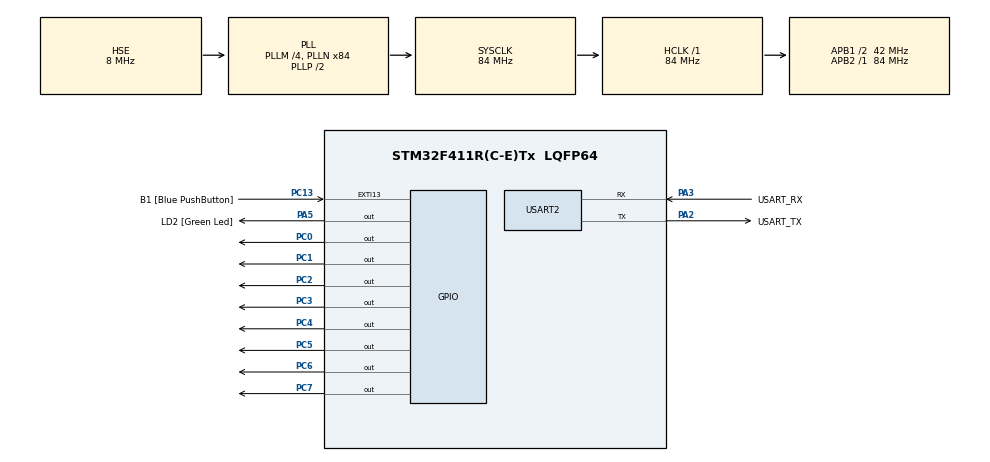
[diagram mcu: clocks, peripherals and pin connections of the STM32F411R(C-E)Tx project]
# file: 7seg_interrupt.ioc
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Mcu.Family=STM32F4
Mcu.Name=STM32F411R(C-E)Tx
Mcu.Package=LQFP64
NVIC.PVD_IRQn=true\:0\:0\:false\:false\:true\:true\:true\:true
NVIC.PriorityGroup=NVIC_PRIORITYGROUP_0
NVIC.TIM2_IRQn=true\:0\:0\:false\:false\:true\:true\:true\:true
PA13.GPIO_Label=TMS
PA13.Mode=Serial_Wire
PA13.Signal=SYS_JTMS-SWDIO
PA14.GPIO_Label=TCK
PA14.Mode=Serial_Wire
PA14.Signal=SYS_JTCK-SWCLK
PA2.GPIO_Label=USART_TX
PA2.Mode=Asynchronous
PA2.Signal=USART2_TX
PA3.GPIO_Label=USART_RX
PA3.Mode=Asynchronous
PA3.Signal=USART2_RX
PA5.GPIO_Label=LD2 [Green Led]
PA5.Signal=GPIO_Output
PB3.GPIO_Label=SWO
PB3.Signal=SYS_JTDO-SWO
PC0.Signal=GPIO_Output
PC1.Signal=GPIO_Output
PC13-ANTI_TAMP.GPIO_Label=B1 [Blue PushButton]
PC13-ANTI_TAMP.GPIO_ModeDefaultEXTI=GPIO_MODE_IT_RISING_FALLING
PC13-ANTI_TAMP.Signal=GPXTI13
PC14-OSC32_IN.Mode=LSE-External-Oscillator
PC14-OSC32_IN.Signal=RCC_OSC32_IN
PC15-OSC32_OUT.Mode=LSE-External-Oscillator
PC15-OSC32_OUT.Signal=RCC_OSC32_OUT
PC2.Signal=GPIO_Output
PC3.Signal=GPIO_Output
PC4.Signal=GPIO_Output
PC5.Signal=GPIO_Output
PC6.Signal=GPIO_Output
PC7.Signal=GPIO_Output
PH0\ -\ OSC_IN.Mode=HSE-External-Clock-Source
PH0\ -\ OSC_IN.Signal=RCC_OSC_IN
PH1\ -\ OSC_OUT.Mode=HSE-External-Clock-Source
PH1\ -\ OSC_OUT.Signal=RCC_OSC_OUT
ProjectManager.HeapSize=0x200
ProjectManager.StackSize=0x400
ProjectManager.TargetToolchain=STM32CubeIDE
RCC.48MHZClocksFreq_Value=42000000
RCC.AHBFreq_Value=84000000
RCC.APB1CLKDivider=RCC_HCLK_DIV2
RCC.APB1Freq_Value=42000000
RCC.APB1TimFreq_Value=84000000
RCC.APB2Freq_Value=84000000
RCC.APB2TimFreq_Value=84000000
RCC.CortexFreq_Value=84000000
RCC.FLatency-AdvancedSettings=FLASH_LATENCY_2
RCC.HCLKFreq_Value=84000000
RCC.HSE_VALUE=8000000
RCC.HSI_VALUE=16000000
RCC.PLLM=4
RCC.PLLN=84
RCC.PLLSourceVirtual=RCC_PLLSOURCE_HSE
RCC.SYSCLKFreq_VALUE=84000000
RCC.SYSCLKSource=RCC_SYSCLKSOURCE_PLLCLK
RCC.VCOOutputFreq_Value=168000000
TIM2.Period=9999
TIM2.Prescaler=8399
USART2.VirtualMode=VM_ASYNC
VP_TIM2_VS_ClockSourceINT.Mode=Internal
board=NUCLEO-F411RE

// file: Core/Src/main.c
/* USER CODE BEGIN Header */
/**
  ******************************************************************************
  * @file           : main.c
  * @brief          : Main program body
  ******************************************************************************
  * @attention
  *
  * Copyright (c) 2024 STMicroelectronics.
  * All rights reserved.
  *
  * This software is licensed under terms that can be found in the LICENSE file
  * in the root directory of this software component.
  * If no LICENSE file comes with this software, it is provided AS-IS.
  *
  ******************************************************************************
  */
/* USER CODE END Header */
#include "main.h"

TIM_HandleTypeDef htim2;
UART_HandleTypeDef huart2;

/* USER CODE BEGIN PV */
static uint8_t currentNumber = 0;
static uint8_t displayEnabled = 1; // Flag to enable or disable the display
/* USER CODE END PV */

void SystemClock_Config(void);
static void MX_GPIO_Init(void);
static void MX_USART2_UART_Init(void);
static void MX_TIM2_Init(void);
/* USER CODE BEGIN PFP */
void EXTI0_IRQHandler(void);
void DisplayNumber(uint8_t number);
void TurnOffDisplay(void);
/* USER CODE END PFP */

int main(void)
{

  /* MCU Configuration--------------------------------------------------------*/

  /* Reset of all peripherals, Initializes the Flash interface and the Systick. */
  HAL_Init();

  /* Configure the system clock */
  SystemClock_Config();

  /* Initialize all configured peripherals */
  MX_GPIO_Init();
  MX_USART2_UART_Init();
  MX_TIM2_Init();

  /* USER CODE BEGIN 2 */
  HAL_TIM_Base_Start_IT(&htim2);  // Start TIM2 with interrupt
  HAL_NVIC_SetPriority(EXTI0_IRQn, 0, 0);  // Set priority for EXTI0 interrupt
  HAL_NVIC_EnableIRQ(EXTI0_IRQn);  // Enable EXTI0 interrupt
  /* USER CODE END 2 */

  /* Infinite loop */
  /* USER CODE BEGIN WHILE */
  while (1)
  {
    if (displayEnabled) {
        // Display is enabled, so TIM2 callback will handle the display update
    } else {
        TurnOffDisplay();
    }
    /* USER CODE END WHILE */
  }
}

void HAL_TIM_PeriodElapsedCallback(TIM_HandleTypeDef *htim)
{
    if (htim->Instance == TIM2) {
        if (displayEnabled) { // Check if display is enabled
            /* Update current number and display */
            currentNumber = (currentNumber + 1) % 10;
            DisplayNumber(currentNumber);
        }
    }
}

void DisplayNumber(uint8_t number)
{
    uint8_t segments[10] = {
        0x3F, // 0
        0x06, // 1
        0x5B, // 2
        0x4F, // 3
        0x66, // 4
        0x6D, // 5
        0x7D, // 6
        0x07, // 7
        0x7F, // 8
        0x6F  // 9
    };
    uint8_t segmentPattern = segments[number];

    HAL_GPIO_WritePin(GPIOC, GPIO_PIN_0, (segmentPattern & 0x01) ? GPIO_PIN_RESET : GPIO_PIN_SET); // Segment A
    HAL_GPIO_WritePin(GPIOC, GPIO_PIN_1, (segmentPattern & 0x02) ? GPIO_PIN_RESET : GPIO_PIN_SET); // Segment B
    HAL_GPIO_WritePin(GPIOC, GPIO_PIN_2, (segmentPattern & 0x04) ? GPIO_PIN_RESET : GPIO_PIN_SET); // Segment C
    HAL_GPIO_WritePin(GPIOC, GPIO_PIN_3, (segmentPattern & 0x08) ? GPIO_PIN_RESET : GPIO_PIN_SET); // Segment D
    HAL_GPIO_WritePin(GPIOC, GPIO_PIN_4, (segmentPattern & 0x10) ? GPIO_PIN_RESET : GPIO_PIN_SET); // Segment E
    HAL_GPIO_WritePin(GPIOC, GPIO_PIN_5, (segmentPattern & 0x20) ? GPIO_PIN_RESET : GPIO_PIN_SET); // Segment F
    HAL_GPIO_WritePin(GPIOC, GPIO_PIN_6, (segmentPattern & 0x40) ? GPIO_PIN_RESET : GPIO_PIN_SET); // Segment G
}

void TurnOffDisplay(void)
{
    // Turn off all segments of the 7-segment display
    HAL_GPIO_WritePin(GPIOC, GPIO_PIN_0|GPIO_PIN_1|GPIO_PIN_2|GPIO_PIN_3|GPIO_PIN_4|GPIO_PIN_5|GPIO_PIN_6, GPIO_PIN_SET);
}

void EXTI0_IRQHandler(void)
{
    HAL_GPIO_EXTI_IRQHandler(B1_Pin); // Handle the interrupt
}

void HAL_GPIO_EXTI_Callback(uint16_t GPIO_Pin)
{
    static uint32_t lastInterruptTime = 0;
    uint32_t currentTime = HAL_GetTick();  // Get current time in milliseconds

    if (GPIO_Pin == B1_Pin)
    {
        if (currentTime - lastInterruptTime > 200)  // 200 ms debounce time
        {
            displayEnabled = !displayEnabled; // Toggle the display enable flag
            HAL_GPIO_TogglePin(LD2_GPIO_Port, LD2_Pin); // Optional: Toggle LED to indicate state
        }
        lastInterruptTime = currentTime;
    }
}

void SystemClock_Config(void)
{
  RCC_OscInitTypeDef RCC_OscInitStruct = {0};
  RCC_ClkInitTypeDef RCC_ClkInitStruct = {0};

  /** Configure the main internal regulator output voltage
  */
  __HAL_RCC_PWR_CLK_ENABLE();
  __HAL_PWR_VOLTAGESCALING_CONFIG(PWR_REGULATOR_VOLTAGE_SCALE1);

  /** Initializes the RCC Oscillators according to the specified parameters
  * in the RCC_OscInitTypeDef structure.
  */
  RCC_OscInitStruct.OscillatorType = RCC_OSCILLATORTYPE_HSE;
  RCC_OscInitStruct.HSEState = RCC_HSE_BYPASS;
  RCC_OscInitStruct.PLL.PLLState = RCC_PLL_ON;
  RCC_OscInitStruct.PLL.PLLSource = RCC_PLLSOURCE_HSE;
  RCC_OscInitStruct.PLL.PLLM = 4;
  RCC_OscInitStruct.PLL.PLLN = 84;
  RCC_OscInitStruct.PLL.PLLP = RCC_PLLP_DIV2;
  RCC_OscInitStruct.PLL.PLLQ = 4;
  if (HAL_RCC_OscConfig(&RCC_OscInitStruct) != HAL_OK)
  {
    Error_Handler();
  }

  /** Initializes the CPU, AHB and APB buses clocks
  */
  RCC_ClkInitStruct.ClockType = RCC_CLOCKTYPE_HCLK|RCC_CLOCKTYPE_SYSCLK
                              |RCC_CLOCKTYPE_PCLK1|RCC_CLOCKTYPE_PCLK2;
  RCC_ClkInitStruct.SYSCLKSource = RCC_SYSCLKSOURCE_PLLCLK;
  RCC_ClkInitStruct.AHBCLKDivider = RCC_SYSCLK_DIV1;
  RCC_ClkInitStruct.APB1CLKDivider = RCC_HCLK_DIV2;
  RCC_ClkInitStruct.APB2CLKDivider = RCC_HCLK_DIV1;

  if (HAL_RCC_ClockConfig(&RCC_ClkInitStruct, FLASH_LATENCY_2) != HAL_OK)
  {
    Error_Handler();
  }
}

static void MX_TIM2_Init(void)
{
  TIM_ClockConfigTypeDef sClockSourceConfig = {0};
  TIM_MasterConfigTypeDef sMasterConfig = {0};

  htim2.Instance = TIM2;
  htim2.Init.Prescaler = 8399;
  htim2.Init.CounterMode = TIM_COUNTERMODE_UP;
  htim2.Init.Period = 9999;
  htim2.Init.ClockDivision = TIM_CLOCKDIVISION_DIV1;
  htim2.Init.AutoReloadPreload = TIM_AUTORELOAD_PRELOAD_DISABLE;
  if (HAL_TIM_Base_Init(&htim2) != HAL_OK)
  {
    Error_Handler();
  }
  sClockSourceConfig.ClockSource = TIM_CLOCKSOURCE_INTERNAL;
  if (HAL_TIM_ConfigClockSource(&htim2, &sClockSourceConfig) != HAL_OK)
  {
    Error_Handler();
  }
  sMasterConfig.MasterOutputTrigger = TIM_TRGO_RESET;
  sMasterConfig.MasterSlaveMode = TIM_MASTERSLAVEMODE_DISABLE;
  if (HAL_TIMEx_MasterConfigSynchronization(&htim2, &sMasterConfig) != HAL_OK)
  {
    Error_Handler();
  }
}

static void MX_USART2_UART_Init(void)
{
  huart2.Instance = USART2;
  huart2.Init.BaudRate = 115200;
  huart2.Init.WordLength = UART_WORDLENGTH_8B;
  huart2.Init.StopBits = UART_STOPBITS_1;
  huart2.Init.Parity = UART_PARITY_NONE;
  huart2.Init.Mode = UART_MODE_TX_RX;
  huart2.Init.HwFlowCtl = UART_HWCONTROL_NONE;
  huart2.Init.OverSampling = UART_OVERSAMPLING_16;
  if (HAL_UART_Init(&huart2) != HAL_OK)
  {
    Error_Handler();
  }
}

static void MX_GPIO_Init(void)
{
  GPIO_InitTypeDef GPIO_InitStruct = {0};

  __HAL_RCC_GPIOC_CLK_ENABLE();
  __HAL_RCC_GPIOH_CLK_ENABLE();
  __HAL_RCC_GPIOA_CLK_ENABLE();
  __HAL_RCC_GPIOB_CLK_ENABLE();

  HAL_GPIO_WritePin(GPIOC, GPIO_PIN_0|GPIO_PIN_1|GPIO_PIN_2|GPIO_PIN_3|GPIO_PIN_4|GPIO_PIN_5|GPIO_PIN_6|GPIO_PIN_7, GPIO_PIN_RESET);
  HAL_GPIO_WritePin(LD2_GPIO_Port, LD2_Pin, GPIO_PIN_RESET);

  /* Configure GPIO pin : B1_Pin */
  GPIO_InitStruct.Pin = B1_Pin;
  GPIO_InitStruct.Mode = GPIO_MODE_IT_RISING_FALLING; // Rising and falling edge
  GPIO_InitStruct.Pull = GPIO_NOPULL; // No pull-up or pull-down resistor
  HAL_GPIO_Init(B1_GPIO_Port, &GPIO_InitStruct);

  /* Configure GPIO pins : PC0 PC1 PC2 PC3 PC4 PC5 PC6 PC7 */
  GPIO_InitStruct.Pin = GPIO_PIN_0|GPIO_PIN_1|GPIO_PIN_2|GPIO_PIN_3|GPIO_PIN_4|GPIO_PIN_5|GPIO_PIN_6|GPIO_PIN_7;
  GPIO_InitStruct.Mode = GPIO_MODE_OUTPUT_PP;
  GPIO_InitStruct.Pull = GPIO_NOPULL;
  GPIO_InitStruct.Speed = GPIO_SPEED_FREQ_LOW;
  HAL_GPIO_Init(GPIOC, &GPIO_InitStruct);

  /* Configure GPIO pin : LD2_Pin */
  GPIO_InitStruct.Pin = LD2_Pin;
  GPIO_InitStruct.Mode = GPIO_MODE_OUTPUT_PP;  // Push-pull output
  GPIO_InitStruct.Pull = GPIO_NOPULL;  // No pull-up or pull-down resistor
  GPIO_InitStruct.Speed = GPIO_SPEED_FREQ_LOW;  // Low speed
  HAL_GPIO_Init(LD2_GPIO_Port, &GPIO_InitStruct);
}

void Error_Handler(void)
{
  __disable_irq();
  while (1)
  {
  }
}
